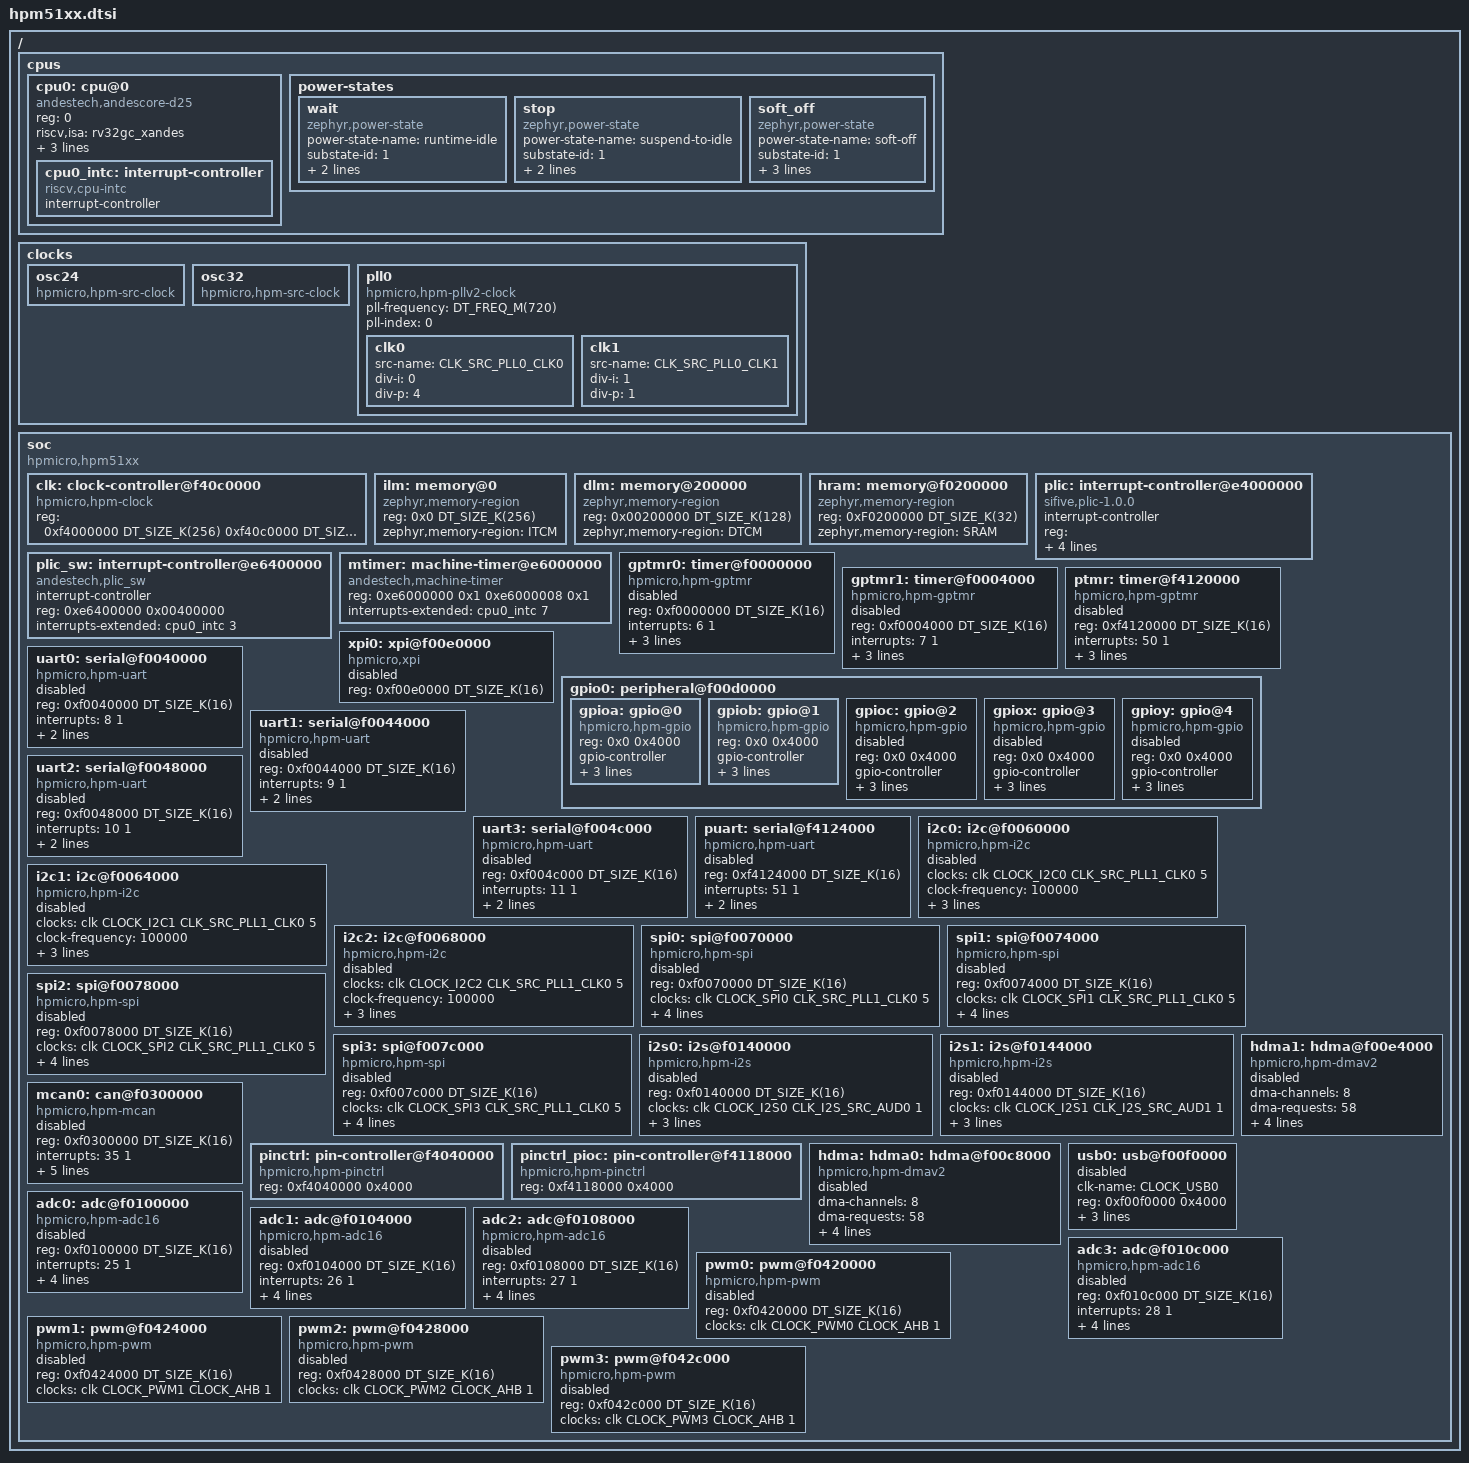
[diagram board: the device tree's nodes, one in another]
/*
 * Copyright 2026 HPMicro
 * SPDX-License-Identifier: Apache-2.0
 */

/dts-v1/;
#include <zephyr/dt-bindings/gpio/gpio.h>
#include <dt-bindings/clock/hpmicro-clocks.h>
#include <dt-bindings/clock/hpm5151-clocks.h>
#include <mem.h>
#include <freq.h>

/ {
	#address-cells = <1>;
	#size-cells = <1>;

	cpus {
		#address-cells = <1>;
		#size-cells = <0>;
		cpu0: cpu@0 {
			compatible = "andestech,andescore-d25", "riscv";
			reg = <0>;
			status = "okay";
			riscv,isa = "rv32gc_xandes";
			i-cache-line-size = <64>;
			d-cache-line-size = <64>;
			cpu-power-states = <&wait &stop &soft_off>;

			cpu0_intc: interrupt-controller {
				compatible = "riscv,cpu-intc";
				#address-cells = <0>;
				#interrupt-cells = <1>;
				interrupt-controller;
			};
		};

		power-states {
			wait: wait {
				compatible = "zephyr,power-state";
				power-state-name = "runtime-idle";
				substate-id = <1>;
				min-residency-us = <10>;
				exit-latency-us = <10>;
			};

			stop: stop {
				compatible = "zephyr,power-state";
				power-state-name = "suspend-to-idle";
				substate-id = <1>;
				min-residency-us = <100>;
				exit-latency-us = <100>;
			};

			soft_off: soft_off {
				compatible = "zephyr,power-state";
				power-state-name = "soft-off";
				substate-id = <1>;
				min-residency-us = <1000>;
				exit-latency-us = <1000>;
				zephyr,pm-device-disabled;
			};
		};
	};

	clocks {
		osc24: osc24 {
			#clock-cells = <2>;
			compatible = "hpmicro,hpm-src-clock";
		};

		osc32: osc32 {
			#clock-cells = <2>;
			compatible = "hpmicro,hpm-src-clock";
		};

		pll0: pll0 {
			#clock-cells = <2>;
			compatible = "hpmicro,hpm-pllv2-clock";
			pll-frequency = <DT_FREQ_M(720)>;
			pll-index = <0>;

			clk0 {
				src-name = <CLK_SRC_PLL0_CLK0>;
				div-i = <0>;
				/* 720 MHz / 1.8 = 400 MHz */
				div-p = <4>;
			};

			clk1 {
				src-name = <CLK_SRC_PLL0_CLK1>;
				div-i = <1>;
				div-p = <1>;
			};
		};

		/*
		 * Do NOT declare pll1 as hpmicro,hpm-pllv2-clock here.
		 * That driver calls sysctl_clock_set_preset() on every PLL
		 * instance; a second PLL node resets the clock tree after
		 * pll0/soc bring-up and yields a silent board (no UART).
		 * ADC ANA uses CLK_SRC_PLL1_CLK0 from BootROM (≈400MHz).
		 */
	};

	soc {
		#address-cells = <1>;
		#size-cells = <1>;
		compatible = "hpmicro,hpm51xx";
		ranges;

		clk: clock-controller@f40c0000 {
			compatible = "hpmicro,hpm-clock";
			reg = <0xf4000000 DT_SIZE_K(256)
				0xf40c0000 DT_SIZE_K(256)>;
			reg-names = "sysctl", "pll";
			#clock-cells = <3>;
			status = "okay";
		};

		ilm: memory@0 {
			compatible = "zephyr,memory-region";
			reg = <0x0 DT_SIZE_K(256)>;
			zephyr,memory-region = "ITCM";
		};

		dlm: memory@200000 {
			compatible = "zephyr,memory-region";
			reg = <0x00200000 DT_SIZE_K(128)>;
			zephyr,memory-region = "DTCM";
		};

		hram: memory@f0200000 {
			compatible = "zephyr,memory-region";
			reg = <0xF0200000 DT_SIZE_K(32)>;
			zephyr,memory-region = "SRAM";
		};

		plic: interrupt-controller@e4000000 {
			compatible = "sifive,plic-1.0.0";
			#address-cells = <1>;
			#interrupt-cells = <2>;
			interrupt-controller;
			reg = <0xe4000000 0x00001000
				0xe4002000 0x00000800
				0xe4200000 0x00010000>;
			reg-names = "prio", "irq_en", "reg";
			riscv,max-priority = <7>;
			riscv,ndev = <72>;
			interrupts-extended = <&cpu0_intc 11>;
		};

		plic_sw: interrupt-controller@e6400000 {
			compatible = "andestech,plic_sw";
			#address-cells = <1>;
			#interrupt-cells = <2>;
			interrupt-controller;
			reg = <0xe6400000 0x00400000>;
			interrupts-extended = <&cpu0_intc 3>;
		};

		mtimer: machine-timer@e6000000 {
			compatible = "andestech,machine-timer";
			reg = <0xe6000000 0x1
				0xe6000008 0x1>;
			interrupts-extended = <&cpu0_intc 7>;
		};

		/*
		 * GPTMRv2: GPTMR0 @ 0xF0000000 IRQn 6, GPTMR1 @ 0xF0004000 IRQn 7.
		 * Prefer GPTMR0 for app counters (PLIC 7 is fine; mtimer uses cpu intc 7).
		 */
		gptmr0: timer@f0000000 {
			compatible = "hpmicro,hpm-gptmr";
			reg = <0xf0000000 DT_SIZE_K(16)>;
			interrupts = <6 1>;
			interrupt-parent = <&plic>;
			clk-name = <CLOCK_GPTMR0>;
			channel = <0>;
			status = "disabled";
		};

		gptmr1: timer@f0004000 {
			compatible = "hpmicro,hpm-gptmr";
			reg = <0xf0004000 DT_SIZE_K(16)>;
			interrupts = <7 1>;
			interrupt-parent = <&plic>;
			clk-name = <CLOCK_GPTMR1>;
			channel = <0>;
			status = "disabled";
		};

		/*
		 * PMIC-domain GPTMRv2. PTMR keeps running in Stop and is the
		 * low-power timer selected by the HPM5151 SDK RTOS ports.
		 */
		ptmr: timer@f4120000 {
			compatible = "hpmicro,hpm-gptmr";
			reg = <0xf4120000 DT_SIZE_K(16)>;
			interrupts = <50 1>;
			interrupt-parent = <&plic>;
			clk-name = <CLOCK_PTMR>;
			channel = <1>;
			status = "disabled";
		};

		xpi0: xpi@f00e0000 {
			compatible = "hpmicro,xpi";
			reg = <0xf00e0000 DT_SIZE_K(16)>;
			#address-cells = <1>;
			#size-cells = <1>;
			status = "disabled";
		};

		gpio0: peripheral@f00d0000 {
			#address-cells = <1>;
			#size-cells = <1>;
			ranges = <0x0 0xf00d0000 DT_SIZE_K(16)>;
		};

		/*
		 * Functional clocks (HPM5100 UM Table 18):
		 * URT/I2C/SPI/CAN: mux=3 (PLL1CLK0@400MHz), reg DIV=4 →
		 * clock_set_source_divider() uses actual divisor = reg+1 = 5
		 * → 80MHz.
		 */
		/*
		 * HPM5151 has on-chip UART RX-line idle; Async idle uses the
		 * UART IRQ only (no GPTMR "idletimer" second interrupt).
		 */
		uart0: serial@f0040000 {
			compatible = "hpmicro,hpm-uart";
			reg = <0xf0040000 DT_SIZE_K(16)>;
			interrupts = <8 1>;
			interrupt-names = "uart";
			clocks = <&clk CLOCK_UART0 CLK_SRC_PLL1_CLK0 5>;
			interrupt-parent = <&plic>;
			status = "disabled";
		};

		uart1: serial@f0044000 {
			compatible = "hpmicro,hpm-uart";
			reg = <0xf0044000 DT_SIZE_K(16)>;
			interrupts = <9 1>;
			interrupt-names = "uart";
			clocks = <&clk CLOCK_UART1 CLK_SRC_PLL1_CLK0 5>;
			interrupt-parent = <&plic>;
			status = "disabled";
		};

		uart2: serial@f0048000 {
			compatible = "hpmicro,hpm-uart";
			reg = <0xf0048000 DT_SIZE_K(16)>;
			interrupts = <10 1>;
			interrupt-names = "uart";
			clocks = <&clk CLOCK_UART2 CLK_SRC_PLL1_CLK0 5>;
			interrupt-parent = <&plic>;
			status = "disabled";
		};

		uart3: serial@f004c000 {
			compatible = "hpmicro,hpm-uart";
			reg = <0xf004c000 DT_SIZE_K(16)>;
			interrupts = <11 1>;
			interrupt-names = "uart";
			clocks = <&clk CLOCK_UART3 CLK_SRC_PLL1_CLK0 5>;
			interrupt-parent = <&plic>;
			status = "disabled";
		};

		/*
		 * PMIC-domain UART. Unlike UART0-3, PUART remains available as a
		 * serial wake source while the SoC is in Stop mode.
		 */
		puart: serial@f4124000 {
			compatible = "hpmicro,hpm-uart";
			reg = <0xf4124000 DT_SIZE_K(16)>;
			interrupts = <51 1>;
			interrupt-names = "uart";
			clocks = <&clk CLOCK_PUART CLK_PWDG_SRC_OSC24M 1>;
			interrupt-parent = <&plic>;
			status = "disabled";
		};

		i2c0: i2c@f0060000 {
			compatible = "hpmicro,hpm-i2c";
			#address-cells = <1>;
			#size-cells = <0>;
			clocks = <&clk CLOCK_I2C0 CLK_SRC_PLL1_CLK0 5>;
			clock-frequency = <100000>;
			reg = <0xf0060000 DT_SIZE_K(16)>;
			interrupts = <12 1>;
			interrupt-parent = <&plic>;
			status = "disabled";
		};

		i2c1: i2c@f0064000 {
			compatible = "hpmicro,hpm-i2c";
			#address-cells = <1>;
			#size-cells = <0>;
			clocks = <&clk CLOCK_I2C1 CLK_SRC_PLL1_CLK0 5>;
			clock-frequency = <100000>;
			reg = <0xf0064000 DT_SIZE_K(16)>;
			interrupts = <13 1>;
			interrupt-parent = <&plic>;
			status = "disabled";
		};

		i2c2: i2c@f0068000 {
			compatible = "hpmicro,hpm-i2c";
			#address-cells = <1>;
			#size-cells = <0>;
			clocks = <&clk CLOCK_I2C2 CLK_SRC_PLL1_CLK0 5>;
			clock-frequency = <100000>;
			reg = <0xf0068000 DT_SIZE_K(16)>;
			interrupts = <14 1>;
			interrupt-parent = <&plic>;
			status = "disabled";
		};

		spi0: spi@f0070000 {
			compatible = "hpmicro,hpm-spi";
			reg = <0xf0070000 DT_SIZE_K(16)>;
			/* SDK / UM Table 18: PLL1CLK0, reg DIV=4 → API div=5 = 80MHz. */
			clocks = <&clk CLOCK_SPI0 CLK_SRC_PLL1_CLK0 5>;
			interrupts = <15 1>;
			interrupt-parent = <&plic>;
			status = "disabled";
			#address-cells = <1>;
			#size-cells = <0>;
			cs-sck-delay = <3>;
			cs-minimum-high-time = <11>;
		};

		spi1: spi@f0074000 {
			compatible = "hpmicro,hpm-spi";
			reg = <0xf0074000 DT_SIZE_K(16)>;
			clocks = <&clk CLOCK_SPI1 CLK_SRC_PLL1_CLK0 5>;
			interrupts = <16 1>;
			interrupt-parent = <&plic>;
			status = "disabled";
			#address-cells = <1>;
			#size-cells = <0>;
			cs-sck-delay = <3>;
			cs-minimum-high-time = <11>;
		};

		spi2: spi@f0078000 {
			compatible = "hpmicro,hpm-spi";
			reg = <0xf0078000 DT_SIZE_K(16)>;
			clocks = <&clk CLOCK_SPI2 CLK_SRC_PLL1_CLK0 5>;
			interrupts = <17 1>;
			interrupt-parent = <&plic>;
			status = "disabled";
			#address-cells = <1>;
			#size-cells = <0>;
			cs-sck-delay = <3>;
			cs-minimum-high-time = <11>;
		};

		spi3: spi@f007c000 {
			compatible = "hpmicro,hpm-spi";
			reg = <0xf007c000 DT_SIZE_K(16)>;
			/* UM Table 18 / SDK: PLL1_CLK0 API div=5 = 80MHz. OSC24M is too slow for Mode3 framed slave. */
			clocks = <&clk CLOCK_SPI3 CLK_SRC_PLL1_CLK0 5>;
			interrupts = <18 1>;
			interrupt-parent = <&plic>;
			status = "disabled";
			#address-cells = <1>;
			#size-cells = <0>;
			cs-sck-delay = <3>;
			cs-minimum-high-time = <11>;
		};

		i2s0: i2s@f0140000 {
			compatible = "hpmicro,hpm-i2s";
			reg = <0xf0140000 DT_SIZE_K(16)>;
			clocks = <&clk CLOCK_I2S0 CLK_I2S_SRC_AUD0 1>;
			dmas = <&hdma 2 0x18>, <&hdma 3 0x14>;
			dma-names = "tx", "rx";
			interrupts = <33 1>;
			interrupt-parent = <&plic>;
			#address-cells = <1>;
			#size-cells = <0>;
			status = "disabled";
		};

		i2s1: i2s@f0144000 {
			compatible = "hpmicro,hpm-i2s";
			reg = <0xf0144000 DT_SIZE_K(16)>;
			clocks = <&clk CLOCK_I2S1 CLK_I2S_SRC_AUD1 1>;
			dmas = <&hdma 4 0x20>, <&hdma 5 0x1c>;
			dma-names = "tx", "rx";
			interrupts = <34 1>;
			interrupt-parent = <&plic>;
			#address-cells = <1>;
			#size-cells = <0>;
			status = "disabled";
		};

		/*
		 * MCAN0 @ 0xF0300000, IRQn 35.
		 * Clock: PLL1_CLK0/5 (same as SDK init_can0_clock).
		 * Message RAM must live in AHB SRAM (HRAM); board uses
		 * zephyr,sram=&hram so BSS buffers are already valid.
		 */
		mcan0: can@f0300000 {
			compatible = "hpmicro,hpm-mcan";
			reg = <0xf0300000 DT_SIZE_K(16)>;
			interrupts = <35 1>;
			interrupt-parent = <&plic>;
			clk-name = <CLOCK_CAN0>;
			clk-source = <CLK_SRC_PLL1_CLK0>;
			clk-divider = <5>;
			bus-speed = <500000>;
			status = "disabled";
		};

		pinctrl: pin-controller@f4040000 {
			compatible = "hpmicro,hpm-pinctrl";
			reg = <0xf4040000 0x4000>;
			status = "okay";
		};

		pinctrl_pioc: pin-controller@f4118000 {
			compatible = "hpmicro,hpm-pinctrl";
			reg = <0xf4118000 0x4000>;
			status = "okay";
		};

		/*
		 * UM: two AHB DMA engines + shared DMAMUX.
		 * HDMA0 @ 0xF00C8000 IRQ24; HDMA1 @ 0xF00E4000 IRQ47;
		 * DMAMUX @ 0xF00C4000 (HDMA0_MUX0..31 then HDMA1_MUX0..31).
		 * Each engine has 32 HW channels (DMA_SOC_CHANNEL_NUM); DT
		 * exposes 8 for bring-up channel budgeting.
		 */
		hdma: hdma0: hdma@f00c8000 {
			#dma-cells = <2>;
			compatible = "hpmicro,hpm-dmav2";
			dma-channels = <8>;
			dma-requests = <58>; /* hpm_sdk v1.13.0 hpm_dmamux_src.h: 0x00..0x39 */
			reg = <0xf00c8000 0x4000>,
				<0xf00c4000 0x4000>;
			clk-name = <CLOCK_HDMA0>;
			interrupts = <24 1>;
			interrupt-parent = <&plic>;
			status = "disabled";
		};

		hdma1: hdma@f00e4000 {
			#dma-cells = <2>;
			compatible = "hpmicro,hpm-dmav2";
			dma-channels = <8>;
			dma-requests = <58>; /* shared DMAMUX, hpm_sdk v1.13.0 hpm_dmamux_src.h: 0x00..0x39 */
			reg = <0xf00e4000 0x4000>,
				<0xf00c4000 0x4000>;
			clk-name = <CLOCK_HDMA1>;
			interrupts = <47 1>;
			interrupt-parent = <&plic>;
			status = "disabled";
		};

		usb0: usb@f00f0000 {
			clk-name = <CLOCK_USB0>;
			reg = <0xf00f0000 0x4000>;
			interrupts = <43 1>;
			interrupt-parent = <&plic>;
			num-bidir-endpoints = <16>;
			status = "disabled";
		};

		adc0: adc@f0100000 {
			compatible = "hpmicro,hpm-adc16";
			reg = <0xf0100000 DT_SIZE_K(16)>;
			interrupts = <25 1>;
			interrupt-parent = <&plic>;
			/* ANA0 ← PLL1_CLK0/2 (BootROM PLL1 ≈400MHz). Prefer AHB for
			 * bring-up if ANA hangs; SDK sample uses bus clock by default.
			 */
			clocks = <&clk CLOCK_ADC0 CLK_ADC_SRC_AHB0 1>,
				 <&clk CLOCK_ANA0 CLK_SRC_PLL1_CLK0 2>;
			sample-time = <20>;
			status = "disabled";
			#io-channel-cells = <1>;
		};

		adc1: adc@f0104000 {
			compatible = "hpmicro,hpm-adc16";
			reg = <0xf0104000 DT_SIZE_K(16)>;
			interrupts = <26 1>;
			interrupt-parent = <&plic>;
			clocks = <&clk CLOCK_ADC1 CLK_ADC_SRC_AHB0 1>,
				 <&clk CLOCK_ANA1 CLK_SRC_PLL1_CLK0 2>;
			sample-time = <20>;
			status = "disabled";
			#io-channel-cells = <1>;
		};

		adc2: adc@f0108000 {
			compatible = "hpmicro,hpm-adc16";
			reg = <0xf0108000 DT_SIZE_K(16)>;
			interrupts = <27 1>;
			interrupt-parent = <&plic>;
			clocks = <&clk CLOCK_ADC2 CLK_ADC_SRC_AHB0 1>,
				 <&clk CLOCK_ANA2 CLK_SRC_PLL1_CLK0 2>;
			sample-time = <20>;
			status = "disabled";
			#io-channel-cells = <1>;
		};

		adc3: adc@f010c000 {
			compatible = "hpmicro,hpm-adc16";
			reg = <0xf010c000 DT_SIZE_K(16)>;
			interrupts = <28 1>;
			interrupt-parent = <&plic>;
			clocks = <&clk CLOCK_ADC3 CLK_ADC_SRC_AHB0 1>,
				 <&clk CLOCK_ANA3 CLK_SRC_PLL1_CLK0 2>;
			sample-time = <20>;
			status = "disabled";
			#io-channel-cells = <1>;
		};

		/* PWM v1 (hpm_pwm_drv): HPM_PWMn @ 0xF042x000, IRQn_PWMn = 37..40 */
		pwm0: pwm@f0420000 {
			compatible = "hpmicro,hpm-pwm";
			reg = <0xf0420000 DT_SIZE_K(16)>;
			clocks = <&clk CLOCK_PWM0 CLOCK_AHB 1>;
			status = "disabled";
			#pwm-cells = <3>;
		};

		pwm1: pwm@f0424000 {
			compatible = "hpmicro,hpm-pwm";
			reg = <0xf0424000 DT_SIZE_K(16)>;
			clocks = <&clk CLOCK_PWM1 CLOCK_AHB 1>;
			status = "disabled";
			#pwm-cells = <3>;
		};

		pwm2: pwm@f0428000 {
			compatible = "hpmicro,hpm-pwm";
			reg = <0xf0428000 DT_SIZE_K(16)>;
			clocks = <&clk CLOCK_PWM2 CLOCK_AHB 1>;
			status = "disabled";
			#pwm-cells = <3>;
		};

		pwm3: pwm@f042c000 {
			compatible = "hpmicro,hpm-pwm";
			reg = <0xf042c000 DT_SIZE_K(16)>;
			clocks = <&clk CLOCK_PWM3 CLOCK_AHB 1>;
			status = "disabled";
			#pwm-cells = <3>;
		};
	};
};

&gpio0 {
	gpioa: gpio@0 {
		compatible = "hpmicro,hpm-gpio";
		reg = <0x0 0x4000>;
		gpio-controller;
		#gpio-cells = <2>;
		hpmicro-gpio-port = <0>;
		interrupts = <1 1>;
		interrupt-parent = <&plic>;
	};

	gpiob: gpio@1 {
		compatible = "hpmicro,hpm-gpio";
		reg = <0x0 0x4000>;
		gpio-controller;
		#gpio-cells = <2>;
		hpmicro-gpio-port = <1>;
		interrupts = <2 1>;
		interrupt-parent = <&plic>;
	};

	gpioc: gpio@2 {
		compatible = "hpmicro,hpm-gpio";
		reg = <0x0 0x4000>;
		gpio-controller;
		#gpio-cells = <2>;
		hpmicro-gpio-port = <2>;
		interrupts = <3 1>;
		interrupt-parent = <&plic>;
		status = "disabled";
	};

	gpiox: gpio@3 {
		compatible = "hpmicro,hpm-gpio";
		reg = <0x0 0x4000>;
		gpio-controller;
		#gpio-cells = <2>;
		hpmicro-gpio-port = <13>;
		interrupt-parent = <&plic>;
		interrupts = <4 1>;
		status = "disabled";
	};

	gpioy: gpio@4 {
		compatible = "hpmicro,hpm-gpio";
		reg = <0x0 0x4000>;
		gpio-controller;
		#gpio-cells = <2>;
		hpmicro-gpio-port = <14>;
		interrupts = <5 1>;
		interrupt-parent = <&plic>;
		status = "disabled";
	};
};
